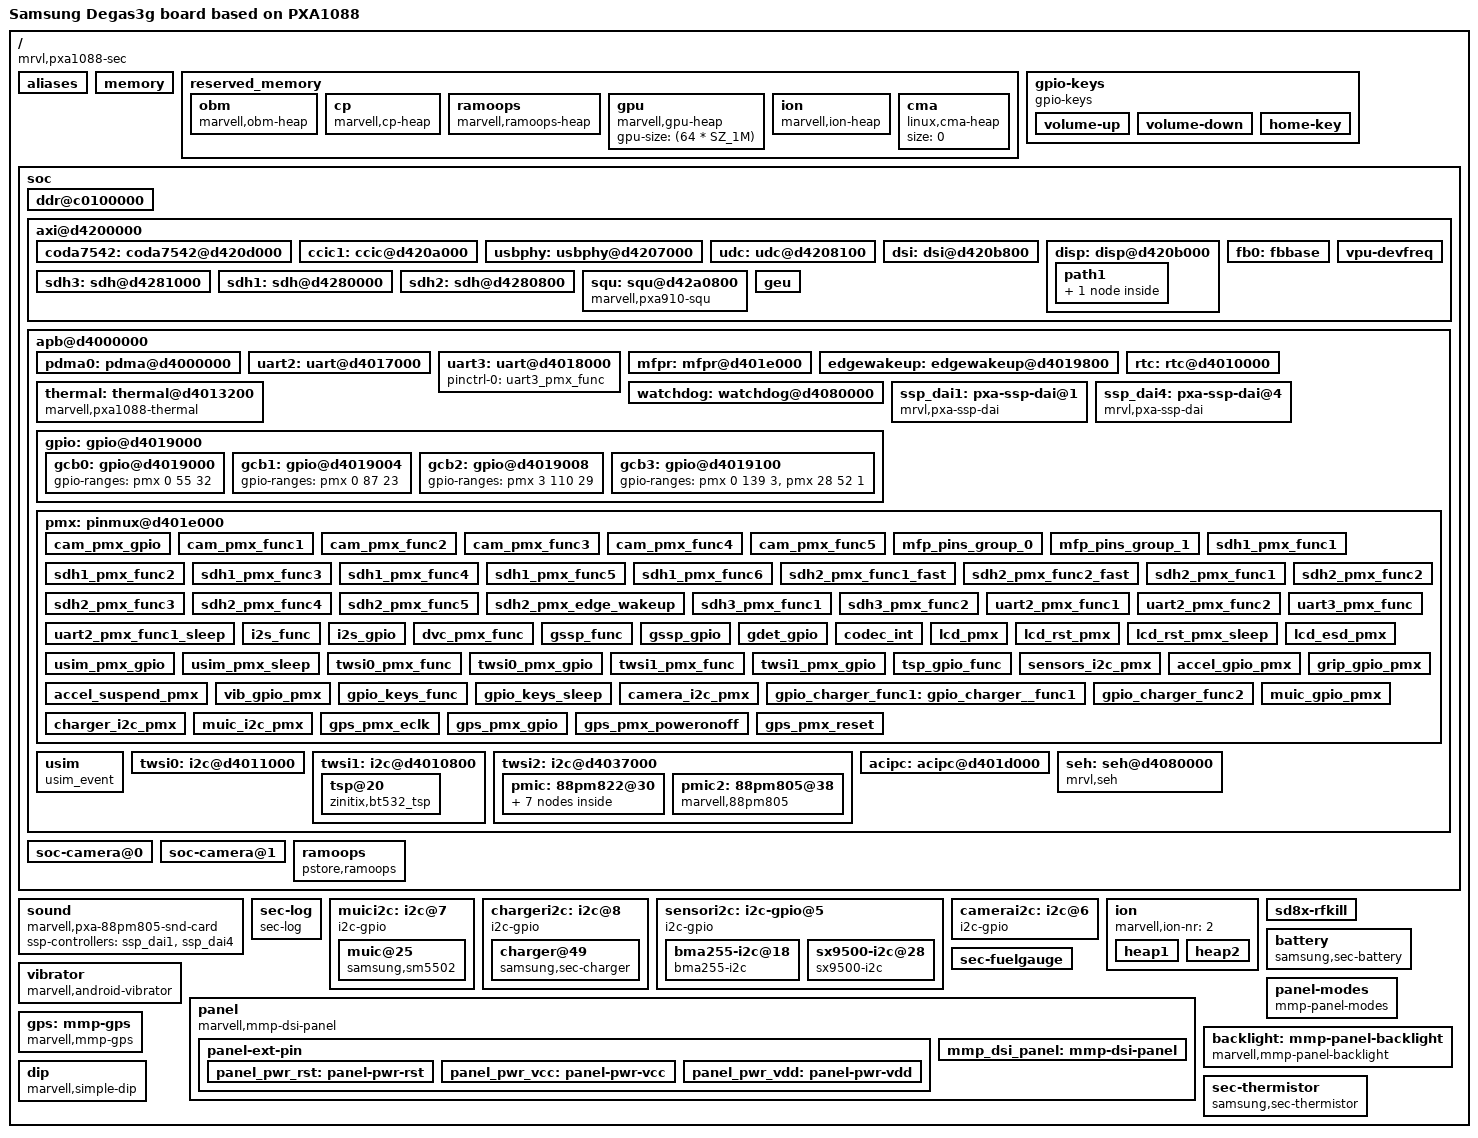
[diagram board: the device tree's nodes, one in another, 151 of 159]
/* arch/arm/boot/dts/pxa1088-degas3g-r01.dts
 * Copyright (C) 2014 Samsung Electronics Co, Ltd.
 *
 * Based on arch/arm/boot/dts/pxa1088-degas3g-r00.dts
 * Author: Shankar Bandal <shankar.b@samsung.com>
 *
 * This software is licensed under the terms of the GNU General Public
 * License version 2, as published by the Free Software Foundation,
 * and may be copied, distributed, and modified under those terms.
 *
 * This program is distributed in the hope that it will be useful,
 * but WITHOUT ANY WARRANTY; without even the implied warranty of
 * MERCHANTABILITY or FITNESS FOR A PARTICULAR PURPOSE. See the
 * GNU General Public License for more details.
 */

/dts-v1/;
#include <dt-bindings/interrupt-controller/irq.h>
#include <dt-bindings/gpio/gpio.h>
#include <dt-bindings/mmc/pxa_sdhci.h>
#include <dt-bindings/linux/sizes.h>
#include <dt-bindings/video/mmp_disp.h>

#include "sec-machtypes.h"
#include "sec-pxa1x88-pinfunc.h"
#include "pxa1088.dtsi"

/ {
	model = "Samsung Degas3g board based on PXA1088";
	compatible = "mrvl,pxa1088-sec", "mrvl,pxa1088";
	pxa,rev-id = <MACH_TYPE_DEGAS3G 1>;

	aliases {
		i2c7 = &muici2c;
		i2c8 = &chargeri2c;
		i2c5 = &sensori2c;
		i2c6 = &camerai2c;
	};

	memory {
		/* Memory Banks
		 * Bank 1 : Base 0x00000000
		 *	    Size 512 MB
		 * Bank 2 : Base 0x20000000
		 *	    Size 512 MB
		 */
		reg = <0x00000000 0x20000000 0x20000000 0x20000000>;
	};

	reserved_memory {

		obm {
			compatible = "marvell,obm-heap";
			obm-base-default = <0x00000000>;
			obm-base-with-tz = <0x01000000>;
			obm-base-with-crash-dump = <0x06000000>;
			obm-size = <(SZ_1M)>;
			status = "okay";
		};

		cp {
			compatible = "marvell,cp-heap";
			cp-base = <0x06000000>;
			cp-size = <(32 * SZ_1M)>;
			status = "okay";
		};

		/* ramoops buffer (256KB) */
		ramoops {
			compatible = "marvell,ramoops-heap";
			ramoops-base = <0x08100000>;
			ramoops-size = <(256 * SZ_1K)>;
			status = "okay";
		};

		gpu {
			compatible = "marvell,gpu-heap";
			gpu-size = <(64 * SZ_1M)>;
			status = "okay";
		};

		ion {
			compatible = "marvell,ion-heap";
			ion-base = <0x09000000>;
			ion-size = <(112 * SZ_1M)>;
			status = "okay";
		};

		cma {
			compatible = "linux,cma-heap";
			size = <0>;
			status = "okay";
		};
	};

	gpio-keys {
		compatible = "gpio-keys";
		pinctrl-names = "default", "sleep";
		pinctrl-0 = <&gpio_keys_func>;
		pinctrl-1 = <&gpio_keys_sleep>;
		edge-wakeup-gpio = <13>;
		status = "okay";
		volume-up {
			label = "Volume_up";
			gpios = <&gpio 1 GPIO_ACTIVE_LOW>;
			linux,code = <115>; /* KEY_VOLUMEUP */
			debounce-interval = <30>;
		};
		volume-down {
			label = "Volume_down";
			gpios = <&gpio 2 GPIO_ACTIVE_LOW>;
			linux,code = <114>;/* KEY_VOLUMEDOWN */
			debounce-interval = <30>;
		};
		home-key {
			label = "Home_key";
			gpios = <&gpio 13 GPIO_ACTIVE_LOW>;
			linux,code = <102>;/* HOME_KEY */
			debounce-interval = <30>;
			gpio-key,wakeup;
		};
	};

	soc {
		ddr@c0100000 {  /* DDR memory controller */
			status = "okay";
		};

		axi@d4200000 {	/* AXI */
			coda7542: coda7542@d420d000 {
				marvell,sram-internal = <1>;
				marvell,nv21_support = <0>;
				status = "okay";
			};
			ccic1: ccic@d420a000 {
				cam_avdd-supply = <&ldo4>;
				cam_io-supply = <&ldo9>;
				cam_core-supply = <&buck5>;
				cam_stby = <&gpio 14 0>;
				cam_rst = <&gpio 15 0>;
				vt_cam_stby = <&gpio 82 0>;
				vt_cam_rst = <&gpio 81 0>;
				pinctrl-names = "default","enable";
				pinctrl-0 = <&cam_pmx_gpio &cam_pmx_func2 &cam_pmx_func3 &cam_pmx_func4 &cam_pmx_func5>;
				pinctrl-1 = <&cam_pmx_func1 &cam_pmx_func2 &cam_pmx_func3 &cam_pmx_func4 &cam_pmx_func5>;
   			       mclk-gpio = <&gpio 77 0>;
				status = "okay";
			};

			usbphy: usbphy@d4207000 {
				status = "okay";
			};

			udc: udc@d4208100 {
				status = "okay";
			};

			dsi: dsi@d420b800 {
				marvell,phy-name = "mmp_dsi1";
				marvell,plat-path-name = "mmp_pnpath";
				marvell,dsi-lanes = <4>;
				marvell,burst-mode = <2>;
				marvell,hbp-en;
				marvell,hfp-en;
				status = "okay";
			};

			disp: disp@d420b000 {
				marvell,disp-name = "disp_name";
				marvell,path-num = <1>;
				lpm-qos-d1p = <PM_QOS_CPUIDLE_BLOCK_AXI>;
				status = "okay";
				path1 {
					marvell,path-name = "mmp_pnpath";
					marvell,overlay-num = <1>;
					marvell,overlay-table = <PN_GRA>;
					marvell,output-type = <PATH_OUT_DSI>;
					marvell,path-config = <0x10>;
					marvell,link-config = <0x1>;
					WVGA {
						disp1_clksrc = "pll1_416m";
						dsipll_clksrc = "pll3";
						pn_sclk_clksrc = "disp1";
					};
				};
			};

			fb0: fbbase {
				marvell,fb-name = "mmp-fb";
				marvell,path-name = "mmp_pnpath";
				marvell,overlay-id = <PN_GRA>;
				marvell,default-pixfmt = <PIXFMT_RGBA888>;
				marvell,buffer-num = <3>;
				marvell,fb-mem = <0x17000000>;
				status = "okay";
			};

			/* eMMC */
			sdh3: sdh@d4281000 {
				pinctrl-names = "default";
				pinctrl-0 = <&sdh3_pmx_func1 &sdh3_pmx_func2>;
				bus-width = <8>;
				non-removable;
				marvell,sdh-pm-runtime-en;
				marvell,sdh-quirks = <(SDHCI_QUIRK_BROKEN_CARD_DETECTION)>;
				marvell,sdh-quirks2 = <(SDHCI_QUIRK2_BUS_CLK_GATE_ENABLED)>;
				marvell,sdh-host-caps = <(MMC_CAP_1_8V_DDR)>;
				marvell,sdh-host-caps2 = <(
							MMC_CAP2_DISABLE_BLK_ASYNC |
							MMC_CAP2_CACHE_CTRL
						)>;
				marvell,sdh-flags = <(
						PXA_FLAG_SD_8_BIT_CAPABLE_SLOT |
						PXA_FLAG_ENABLE_CLOCK_GATING |
						PXA_FLAG_TX_SEL_BUS_CLK
					      )>;
				/* prop "sdh-dtr-data": <timing preset_rate src_rate tx_delay rx_delay> */
				marvell,sdh-dtr-data = <PXA_MMC_TIMING_LEGACY PXA_SDH_DTR_26M PXA_SDH_DTR_104M 0 0>,
						<PXA_MMC_TIMING_MMC_HS PXA_SDH_DTR_52M PXA_SDH_DTR_104M 0 0>,
						<PXA_MMC_TIMING_UHS_DDR50 PXA_SDH_DTR_52M PXA_SDH_DTR_104M 0 0>,
						<PXA_MMC_TIMING_MAX PXA_SDH_DTR_PS_NONE PXA_SDH_DTR_104M 0 0>;
				status = "okay";
			};

			/* SD card */
			sdh1: sdh@d4280000 {
				pinctrl-names = "default";
				pinctrl-0 = <&sdh1_pmx_func1 &sdh1_pmx_func2 &sdh1_pmx_func3 &sdh1_pmx_func4 &sdh1_pmx_func5 &sdh1_pmx_func6>;
				vqmmc-supply	= <&ldo5>;
				vmmc-supply	= <&ldo11>;
				cd-gpios = <&gpio 11 0>;
				cd-inverted;
				bus-width = <4>;
				wp-inverted;
				marvell,sdh-pm-runtime-en;
				marvell,sdh-host-caps-disable = <(
					MMC_CAP_UHS_SDR12
					|MMC_CAP_UHS_SDR25
					|MMC_CAP_UHS_SDR50
					|MMC_CAP_UHS_DDR50
					|MMC_CAP_UHS_SDR104
				)>;
				marvell,sdh-quirks = <(
						SDHCI_QUIRK_INVERTED_WRITE_PROTECT |
						SDHCI_QUIRK_BROKEN_CARD_DETECTION
						)>;
				marvell,sdh-quirks2 = <(SDHCI_QUIRK2_BUS_CLK_GATE_ENABLED)>;
				marvell,sdh-host-caps2 = <(MMC_CAP2_DETECT_ON_ERR)>;
				marvell,sdh-flags = <(
						PXA_FLAG_TX_SEL_BUS_CLK |
						PXA_FLAG_ENABLE_CLOCK_GATING
					      )>;
				/* prop "sdh-dtr-data": <timing preset_rate src_rate tx_delay rx_delay> */
				marvell,sdh-dtr-data = <PXA_MMC_TIMING_LEGACY PXA_SDH_DTR_26M PXA_SDH_DTR_104M 0 0>,
						<PXA_MMC_TIMING_SD_HS PXA_SDH_DTR_52M PXA_SDH_DTR_104M 0 0>,
						<PXA_MMC_TIMING_UHS_DDR50 PXA_SDH_DTR_52M PXA_SDH_DTR_104M 0 0>,
						<PXA_MMC_TIMING_MAX PXA_SDH_DTR_PS_NONE PXA_SDH_DTR_104M 0 0>;
				status = "okay";
			};

			/* SDIO */
			sdh2: sdh@d4280800 {
				pinctrl-names = "default", "fast", "sleep";
				pinctrl-0 = <&sdh2_pmx_func1 &sdh2_pmx_func2 &sdh2_pmx_func3 &sdh2_pmx_func4 &sdh2_pmx_func5>;
				pinctrl-1 = <&sdh2_pmx_func1_fast &sdh2_pmx_func2_fast &sdh2_pmx_func3 &sdh2_pmx_func4 &sdh2_pmx_func5>;
				pinctrl-2 = <&sdh2_pmx_edge_wakeup>;
				bus-width = <4>;
				mrvl,clk-delay-cycles = <0x0>;
				marvell,sdh-quirks = <(
						SDHCI_QUIRK_BROKEN_CARD_DETECTION
						)>;
				marvell,sdh-quirks2 = <(
				        SDHCI_QUIRK2_BUS_CLK_GATE_ENABLED |
				        SDHCI_QUIRK2_SDIO_SW_CLK_GATE |
				        SDHCI_QUIRK2_HOLDSUSPEND_AFTER_REQUEST
				        )>;
				marvell,sdh-host-caps2 = <(MMC_CAP2_NO_VOLTAGE_SWITCH)>;
				marvell,sdh-flags = <(
						PXA_FLAG_WAKEUP_HOST |
						PXA_FLAG_ENABLE_CLOCK_GATING |
						PXA_FLAG_TX_SEL_BUS_CLK |
						PXA_FLAG_EN_PM_RUNTIME |
						PXA_FLAG_DISABLE_PROBE_CDSCAN
					    )>;
				marvell,sdh-pm-caps = <(
			            MMC_PM_KEEP_POWER
			            )>;
				/* prop "sdh-dtr-data": <timing preset_rate src_rate tx_delay rx_delay> */
				marvell,sdh-dtr-data = <PXA_MMC_TIMING_LEGACY PXA_SDH_DTR_26M PXA_SDH_DTR_104M 0 0>,
						<PXA_MMC_TIMING_SD_HS PXA_SDH_DTR_45M PXA_SDH_DTR_89M 0 0>,
						<PXA_MMC_TIMING_UHS_SDR104 PXA_SDH_DTR_208M PXA_SDH_DTR_208M 0 0>,
						<PXA_MMC_TIMING_MAX PXA_SDH_DTR_PS_NONE PXA_SDH_DTR_89M 0 0>;
				status = "okay";
			};

			squ: squ@d42a0800 {
				compatible = "marvell,pxa910-squ";
				reg = <0xd42a0800 0x100>;
				interrupts = <0 46 0x4>;
				#dma-cells = <1>;
				asram = <&sram>;
			};

			vpu-devfreq {
				status = "okay";
			};
			geu: geu {
				status = "okay";
			};
		};

		apb@d4000000 {
			pdma0: pdma@d4000000 {
				status = "okay";
			};

			uart2: uart@d4017000 {
				pinctrl-names = "default", "sleep";
				pinctrl-0 = <&uart2_pmx_func1 &uart2_pmx_func2>;
				pinctrl-1 = <&uart2_pmx_func1_sleep &uart2_pmx_func2>;
				edge-wakeup-gpio = <47>; /* GPIO47: UART rx pin */
				status = "okay";
			};

			uart3: uart@d4018000 {
				pinctrl-names = "default";
				pinctrl-0 = <&uart3_pmx_func>;
				status = "okay";
			};

			mfpr: mfpr@d401e000 {
				pinctrl-names = "default";
				reg = <0xd401e000 0x280>;
				pinctrl-0 = <&mfp_pins_group_0 &mfp_pins_group_1>;
				status = "ok";
			};

			edgewakeup: edgewakeup@d4019800 {
				status = "ok";
			};

			rtc: rtc@d4010000 {
				status = "okay";
			};

			thermal: thermal@d4013200 {
				compatible = "marvell,pxa1088-thermal";
				reg = <0xd4013200 0x50>;
				interrupts = <0 60 0x4>;
				trigger_levels_count = <0>;
				type = <0>;
				status = "ok";
			};

			watchdog: watchdog@d4080000 {
				status = "okay";
			};

			ssp_dai1: pxa-ssp-dai@1 {
				compatible = "mrvl,pxa-ssp-dai";
				reg = <0x1 0x0>;
				port = <&ssp1>;
				pinctrl-names = "default","ssp";
				pinctrl-0 = <&i2s_gpio>;
				pinctrl-1 = <&i2s_func>;
				ssp-gpio = <&gpio 21 0 &gpio 22 0 &gpio 23 0 &gpio 24 0>;
				dmas = <&squ 1
					&squ 0>;
				dma-names = "rx", "tx";
				asram = <&sram>;
				platform_driver_name = "tdma_platform";
				burst_size = <4>;
				playback_period_bytes = <4096>;
				playback_buffer_bytes = <20480>;
				capture_period_bytes = <4096>;
				capture_buffer_bytes = <20480>;
			};

			ssp_dai4: pxa-ssp-dai@4 {
				compatible = "mrvl,pxa-ssp-dai";
				reg = <0x4 0x0>;
				port = <&ssp4>;
				pinctrl-names = "default","ssp";
				pinctrl-0 = <&gssp_gpio>;
				pinctrl-1 = <&gssp_func>;
				ssp-gpio = <&gpio 25 0 &gpio 26 0 &gpio 27 0 &gpio 28 0>;
				dmas = <&pdma0 6 0
					&pdma0 7 0>;
				dma-names = "rx", "tx";
				platform_driver_name = "pdma_platform";
				burst_size = <8>;
				playback_period_bytes = <4096>;
				playback_buffer_bytes = <131072>;
				capture_period_bytes = <4096>;
				capture_buffer_bytes = <131072>;
			};

			gpio: gpio@d4019000 {
				status = "okay";
				/*
				 * In theorical, some gpios could be routed to
				 * multiple pins. So define the gpio-ranges in
				 * board file, not silicon file.
				 */
				gcb0: gpio@d4019000 {
					/* gpio offset, pin offset, nr pins */
					gpio-ranges = <&pmx 0 55 32>;
				};
				gcb1: gpio@d4019004 {
					gpio-ranges = <&pmx 0 87 23>;
				};
				gcb2: gpio@d4019008 {
					gpio-ranges = <&pmx 3 110 29>;
				};
				gcb3: gpio@d4019100 {
					gpio-ranges = <&pmx 0 139 3  &pmx 28 52 1>;
				};
			};

			pmx: pinmux@d401e000 {
				/* pin base, nr pins & gpio function */
				pinctrl-single,gpio-range = <
					/*
					 * GPIO number is hardcoded for range at here.
					 * In gpio chip, GPIO number is not hardcoded for range.
					 * Since one gpio pin may be routed to multiple pins,
					 * define these gpio range in pxa910-dkb.dts not pxa910.dtsi.
					 */
					&range 55 55 0	/* GPIO0 ~ GPIO54 */
					&range 110 32 0 /* GPIO67 ~ GPIO98 */
					&range 17 1 1   /* GPIO101 */
					&range 52 1 0	/* GPIO124 */
				>;

				cam_pmx_gpio: cam_pmx_gpio {
					pinctrl-single,pins = <
						GPIO77 AF0
					>;
					DS_MEDIUM;PULL_DOWN;EDGE_NONE;LPM_DRIVE_LOW;
				};
				cam_pmx_func1: cam_pmx_func1 {
					pinctrl-single,pins = <
						GPIO77 AF1
					>;
					DS_SLOW1;PULL_DOWN;EDGE_NONE;LPM_DRIVE_LOW;
				};
				cam_pmx_func2: cam_pmx_func2 {
					pinctrl-single,pins = <
						GPIO67 AF1
						GPIO68 AF1
						GPIO69 AF1
						GPIO70 AF1
						GPIO71 AF1
						GPIO72 AF1
						GPIO73 AF1
						GPIO74 AF1
						GPIO75 AF1
						GPIO76 AF1
					>;
					MFP_LPM_DRIVE_LOW;
				};

				cam_pmx_func3: cam_pmx_func3 {
					pinctrl-single,pins = <
						GPIO78 AF1
					>;
					PULL_DOWN;
				};

				cam_pmx_func4: cam_pmx_func4 {
					pinctrl-single,pins = <
						GPIO14 AF0
						GPIO15 AF0
					>;
					DS_MEDIUM;PULL_DOWN;EDGE_NONE;LPM_DRIVE_LOW;
				};

				cam_pmx_func5: cam_pmx_func5 {
					pinctrl-single,pins = <
						GPIO81 AF0
						GPIO82 AF0
					>;
					DS_MEDIUM;PULL_DOWN;EDGE_NONE;LPM_DRIVE_LOW;
				};

				/* MFP_LPM_FLOAT */
				mfp_pins_group_0: mfp_pins_group_0 {
					pinctrl-single,pins = <
						DF_IO8 AF1
						DF_IO9 AF1
						DF_IO10 AF1
						DF_IO11 AF1
						DF_IO12 AF1
						DF_IO13 AF1
						DF_WEn AF0
						DF_REn AF0
						DF_ALE_SM_WEn AF0
						DF_RDY0 AF1
						DF_RDY1 AF0
						DF_nCS1_SM_nCS3 AF1
						SM_nCS0 AF1
						SM_nCS1 AF1
						GPIO98 AF0
						GPIO123 AF1
						SM_BE0 AF0
						VCXO_REQ AF1
					>;
					PULL_UP;LPM_FLOAT;
				};

				mfp_pins_group_1: mfp_pins_group_1 {
					pinctrl-single,pins = <
						GPIO9 AF0
						DF_IO14 AF1
						DF_IO15 AF1
					>;
					PULL_NONE;LPM_FLOAT;
				};

				/* MFP_PULL_LOW | MFP_LPM_FLOAT */
				sdh1_pmx_func1: sdh1_pmx_func1 {
					pinctrl-single,pins = <
						MMC1_DAT7 AF0
						MMC1_DAT6 AF0
						MMC1_DAT5 AF0
						MMC1_DAT4 AF0
						MMC1_WP AF0
					>;
					DS_MEDIUM;PULL_DOWN;EDGE_NONE;LPM_FLOAT;
				};

				/* no pull, no LPM */
				sdh1_pmx_func2: sdh1_pmx_func2 {
					pinctrl-single,pins = <
						MMC1_DAT3 AF0
						MMC1_DAT2 AF0
						MMC1_DAT1 AF0
						MMC1_DAT0 AF0
					>;
					MFP_DEFAULT;
				};

				/* MFP_LPM_DRIVE_LOW */
				sdh1_pmx_func3: sdh1_pmx_func3 {
					pinctrl-single,pins = <
						MMC1_CLK AF0
					>;
					MFP_LPM_DRIVE_LOW;
				};

				/* MFP_PULL_HIGH */
				sdh1_pmx_func4: sdh1_pmx_func4 {
					pinctrl-single,pins = <
						MMC1_CD AF0
					>;
					DS_MEDIUM;PULL_HIGH;EDGE_NONE;LPM_NONE;
				};

				/* MFP_PULL_UP */
				sdh1_pmx_func5: sdh1_pmx_func5 {
					pinctrl-single,pins = <
						MMC1_CMD AF0
					>;
					PULL_UP;LPM_FLOAT;
				};

				/* SD_DETECT */
				sdh1_pmx_func6: sdh1_pmx_func6 {
					pinctrl-single,pins = <
						GPIO11 AF0
					>;
					MFP_LPM_FLOAT;
				};

				sdh2_pmx_func1_fast: sdh2_pmx_func1_fast {
						pinctrl-single,pins = <
							GPIO37 AF1
							GPIO38 AF1
							GPIO39 AF1
							GPIO40 AF1
							GPIO41 AF1
						>;
						DS_SLOW0;PULL_NONE;EDGE_NONE;LPM_NONE;
				};

				sdh2_pmx_func2_fast: sdh2_pmx_func2_fast {
						pinctrl-single,pins = <
							GPIO42 AF1
						>;
						DS_SLOW0;PULL_NONE;EDGE_NONE;LPM_DRIVE_LOW;
				};

				sdh2_pmx_func1: sdh2_pmx_func1 {
					pinctrl-single,pins = <
						GPIO37 AF1
						GPIO38 AF1
						GPIO39 AF1
						GPIO40 AF1
						GPIO41 AF1
					>;
					DS_SLOW0;PULL_NONE;EDGE_NONE;LPM_NONE;
				};
				/* WLAN_WU_HOST */
				sdh2_pmx_func2: sdh2_pmx_func2 {
					pinctrl-single,pins = <
						GPIO84 AF0
					>;
					DS_MEDIUM;PULL_DOWN;EDGE_NONE;LPM_NONE;
				};
				/* WLAN_PDn */
				sdh2_pmx_func3: sdh2_pmx_func3 {
					pinctrl-single,pins = <
						GPIO51 AF0
					>;
					DS_MEDIUM;PULL_FLOAT;EDGE_NONE;
				};
				/* HOST_WU_WLAN */
				sdh2_pmx_func4: sdh2_pmx_func4 {
					pinctrl-single,pins = <
						GPIO83 AF0
					>;
					DS_MEDIUM;PULL_FLOAT;EDGE_NONE;LPM_DRIVE_LOW;
				};
				/* WLAN_SD_CLK */
				sdh2_pmx_func5: sdh2_pmx_func5 {
					pinctrl-single,pins = <
						GPIO42 AF1
					>;
					DS_SLOW0;PULL_NONE;EDGE_NONE;LPM_DRIVE_LOW;
				};

				sdh2_pmx_edge_wakeup: sdh2_pmx_edge_wakeup {
						pinctrl-single,pins = <
							GPIO39 AF1
						>;
						DS_MEDIUM;PULL_LOW;EDGE_BOTH;LPM_NONE;
				};

				/* no pull, no LPM */
				sdh3_pmx_func1: sdh3_pmx_func1 {
					pinctrl-single,pins = <
						ND_IO7 AF1
						ND_IO6 AF1
						ND_IO5 AF1
						ND_IO4 AF1
						ND_IO3 AF1
						ND_IO2 AF1
						ND_IO1 AF1
						ND_IO0 AF1
						ND_CLE_SM_OEN AF1
						SM_BEN0 AF2
					>;
					DS_MEDIUM;PULL_UP;EDGE_NONE;LPM_FLOAT;
				};

				/* MFP_LPM_DRIVE_LOW */
				sdh3_pmx_func2: sdh3_pmx_func2 {
					pinctrl-single,pins = <
						SM_SCLK AF1
					>;
					MFP_LPM_DRIVE_LOW;
				};

				uart2_pmx_func1: uart2_pmx_func1 {
					pinctrl-single,pins = <
						GPIO47 AF6
					>;
					MFP_PULL_UP;
				};

				uart2_pmx_func2: uart2_pmx_func2 {
					pinctrl-single,pins = <
						GPIO48 AF6
					>;
					MFP_PULL_UP;
				};

				uart2_pmx_func1_sleep: uart2_pmx_func1_sleep {
					pinctrl-single,pins = <
						GPIO47 AF6
					>;
					MFP_PULL_UP;
				};

				uart3_pmx_func: uart3_pmx_func {
					pinctrl-single,pins = <
						GPIO45 AF1
						GPIO46 AF1
					>;
					MFP_DEFAULT;
				};

				i2s_func: i2s_func {
					pinctrl-single,pins = <
						GPIO21 AF1
						GPIO22 AF1
						GPIO23 AF1
						GPIO24 AF1
					>;
					MFP_PULL_UP;
				};

				i2s_gpio: i2s_gpio {
					pinctrl-single,pins = <
						GPIO21 AF0
						GPIO22 AF0
						GPIO23 AF0
						GPIO24 AF0
					>;
					MFP_PULL_UP;
				};

				/* no pull, no LPM */
				dvc_pmx_func: dvc_pmx_func {
					pinctrl-single,pins = <
						GPIO43 AF6
						GPIO44 AF6
					>;
					MFP_DEFAULT;
				};

				gssp_func: gssp_func {
					pinctrl-single,pins = <
						GPIO25 AF1
						GPIO26 AF1
						GPIO27 AF1
						GPIO28 AF1
					>;
					MFP_DEFAULT;
				};

				gssp_gpio: gssp_gpio {
					pinctrl-single,pins = <
						GPIO25 AF0
						GPIO26 AF0
						GPIO27 AF0
						GPIO28 AF0
					>;
					MFP_PULL_UP;
				};

				gdet_gpio: gdet_gpio {
					pinctrl-single,pins = <
						GPIO97 AF0
					>;
					MFP_PULL_UP;LPM_PULLHIGH;
				};
				
				codec_int: codec_int {
					pinctrl-single,pins = <
						GPIO124 AF0
					>;
					MFP_PULL_UP;LPM_PULLHIGH;
				};

				/* MFP_LPM_FLOAT */
				lcd_pmx: lcd_pmx {
					pinctrl-single,pins = <
						GPIO6 AF0
						GPIO7 AF0
					>;
					DS_MEDIUM;PULL_FLOAT;EDGE_NONE;LPM_DRIVE_LOW;
				};

				/* MFP_PULL_UP */
				lcd_rst_pmx: lcd_rst_pmx {
					pinctrl-single,pins = <
						GPIO18 AF0
					>;
					MFP_PULL_UP;
				};

				/* MFP_PULL_LOW | MFP_LPM_DRIVE_LOW */
				lcd_rst_pmx_sleep: lcd_rst_pmx_sleep {
					pinctrl-single,pins = <
						GPIO18 AF0
					>;
					DS_MEDIUM;PULL_DOWN;EDGE_NONE;LPM_DRIVE_LOW;
				};

				lcd_esd_pmx: lcd_esd_pmx {
					pinctrl-single,pins = <
						GPIO19 AF0
					>;
					DS_MEDIUM;PULL_NONE;EDGE_NONE;LPM_DRIVE_HIGH;
				};

				/* MFP_LPM_FLOAT SIM Detect Pin */
				usim_pmx_gpio: usim_pmx_gpio {
					pinctrl-single,pins = <
						GPIO101 AF1
					>;
					DS_MEDIUM;PULL_UP;EDGE_NONE;LPM_FLOAT;
				};
				
				usim_pmx_sleep: usim_pmx_sleep {
					pinctrl-single,pins = <
						GPIO101 AF1
					>;
					DS_MEDIUM;PULL_UP;EDGE_BOTH;LPM_NONE;
				};

				twsi0_pmx_func: twsi0_pmx_func {
					pinctrl-single,pins = <
						GPIO79 AF1
						GPIO80 AF1
					>;
					MFP_LPM_FLOAT;
				};
				twsi0_pmx_gpio: twsi0_pmx_gpio {
					pinctrl-single,pins = <
						GPIO79 AF0
						GPIO80 AF0
					>;
					MFP_LPM_FLOAT;
				};
				twsi1_pmx_func: twsi1_pmx_func {
					pinctrl-single,pins = <
						GPIO87 AF5
						GPIO88 AF5
					>;
					MFP_LPM_FLOAT;
				};

				twsi1_pmx_gpio: twsi1_pmx_gpio {
					pinctrl-single,pins = <
						GPIO87 AF0
						GPIO88 AF0
					>;
					MFP_LPM_FLOAT;
				};
				tsp_gpio_func: tsp_gpio_func {
					pinctrl-single,pins = <
						GPIO94 AF0
					>;
					MFP_DEFAULT;
				};

				sensors_i2c_pmx: sensors_i2c_pmx {
					pinctrl-single,pins = <
						GPIO35 AF0
						GPIO36 AF0
					>;
					DS_MEDIUM;EDGE_NONE;PULL_NONE;LPM_FLOAT;
				};

				accel_gpio_pmx: accel_gpio_pmx {
					pinctrl-single,pins = <
						GPIO10 AF0
					>;
					DS_MEDIUM;PULL_DOWN;EDGE_NONE;
				};

				accel_suspend_pmx: accel_suspend_pmx {
					pinctrl-single,pins = <
						GPIO10 AF0
					>;
					DS_MEDIUM;PULL_DOWN;EDGE_NONE;
				};

				grip_gpio_pmx: grip_gpio_pmx {
					pinctrl-single,pins = <
						GPIO34 AF0
					>;
					DS_MEDIUM;PULL_UP;EDGE_NONE;
				};

				vib_gpio_pmx: vib_gpio_pmx {
					pinctrl-single,pins = <
						GPIO96 AF0
					>;
					MFP_PULL_DOWN;
				};

				gpio_keys_func: gpio_keys_func{
					pinctrl-single,pins = <
						GPIO1 AF0
						GPIO2 AF0
						GPIO13 AF0
					>;
					DS_MEDIUM;PULL_NONE;EDGE_NONE;LPM_FLOAT;
				};

				gpio_keys_sleep: gpio_keys_sleep {
					pinctrl-single,pins = <
						GPIO13 AF0
					>;
					DS_MEDIUM;PULL_UP;EDGE_BOTH;LPM_NONE;
				};

				camera_i2c_pmx: camera_i2c_pmx {
					pinctrl-single,pins = <
						GPIO30 AF0
						GPIO29 AF0
					>;
					MFP_LPM_FLOAT;
				};
				gpio_charger_func1: gpio_charger__func1 {
					pinctrl-single,pins = <
						GPIO8 AF0
						>;
					MFP_DEFAULT;
				};

				gpio_charger_func2: gpio_charger_func2 {
					pinctrl-single,pins = <
						GPIO20 AF0
					>;
					DS_MEDIUM;PULL_DOWN;EDGE_NONE;LPM_NONE;
				};
				muic_gpio_pmx: muic_gpio_pmx {
					pinctrl-single,pins = <
						GPIO93 AF0
					>;
					MFP_LPM_FLOAT;
				};

				charger_i2c_pmx: charger_i2c_pmx {
					pinctrl-single,pins = <
						GPIO17 AF0
						GPIO16 AF0
					>;
					DS_MEDIUM;PULL_UP;EDGE_NONE;LPM_FLOAT;
				};

				muic_i2c_pmx: muic_i2c_pmx {
					pinctrl-single,pins = <
						GPIO50 AF0
						GPIO49 AF0
					>;
					MFP_LPM_FLOAT;
				};
				gps_pmx_eclk: gps_pmx_eclk {
					/* eclk */
					pinctrl-single,pins = <
						GPIO89 AF5
					>;
					MFP_DEFAULT;
				};
				gps_pmx_gpio: gps_pmx_gpio {
					/* gpio */
					pinctrl-single,pins = <
						GPIO89 AF0
					>;
					MFP_DEFAULT;
				};
				gps_pmx_poweronoff: gps_pmx_poweronoff {
					pinctrl-single,pins = <
						GPIO4 AF0
					>;
					MFP_PULL_DOWN;MFP_LPM_DIRVE_LOW;
				};
				gps_pmx_reset: gps_pmx_reset {
					pinctrl-single,pins = <
						GPIO5 AF0
					>;
					MFP_PULL_UP;MFP_LPM_DIRVE_HIGH;
				};
			};

			usim: usim {
				compatible = "usim_event";
				pinctrl-names = "default", "sleep";
				pinctrl-0 = <&usim_pmx_gpio>;
				pinctrl-1 = <&usim_pmx_sleep>;
				edge-wakeup-gpio = <101>;
				status = "okay";
			};

			twsi0: i2c@d4011000 {
				pinctrl-names = "default","gpio";
				pinctrl-0 = <&twsi0_pmx_func>;
				pinctrl-1 = <&twsi0_pmx_gpio>;
				i2c-gpio = <&gpio 79 0 &gpio 80 0>;
				marvell,i2c-always-on;
				status = "okay";
			};

			twsi1: i2c@d4010800 {
				pinctrl-names = "default", "gpio";
				pinctrl-0 = <&twsi1_pmx_func>;
				pinctrl-1 = <&twsi1_pmx_gpio>;
				i2c-gpio = <&gpio 87 0 &gpio 88 0>;
				marvell,i2c-always-on;
				status = "okay";
				tsp@20 {
					compatible = "zinitix,bt532_tsp";
					pinctrl-names = "default";
					pinctrl-0 = <&tsp_gpio_func>;
					reg = <0x20>;
					interrupt-parent = <&gpio>;
					interrupts = <94 IRQ_TYPE_EDGE_FALLING>;
					bt532,x_resolution = /bits/ 16 <799>;
					bt532,y_resolution = /bits/ 16 <1279>;
					bt532,orientation = /bits/ 8 <0>;
					bt532,page_size = /bits/ 16 <128>;
					tsp_gpio = <&gpio 94 GPIO_ACTIVE_LOW>;
					tsp_vdd_supply_type = <1>;
					tsp_vdd-supply = <&ldo1>;
				};
			};

			twsi2: i2c@d4037000 {
				status = "okay";

				pmic: 88pm822@30 {
					reg = <0x30>;
					interrupts = <0 4 0x4>;
					interrupt-parent = <&gic>;
					dvc {
						compatible = "marvell,88pm8xx-dvc";
						/* pm822 dvc affect buck1/3/5, affected 32bit = (1 << 4) | (1 << 2) | (1 << 0)*/
						dvc-affected-buckbits = <21>;
						pinctrl-names = "default";
						pinctrl-0 = <&dvc_pmx_func>;
					};
					usb: usb {
						compatible = "marvell,88pm80x-usb";
						vbus-gpio = <0xff>;
						id-gpadc = <0xff>;
					};

				};
				pmic2: 88pm805@38 {
					compatible = "marvell,88pm805";
					reg = <0x38>;
					interrupt-parent = <&gpio>;
					interrupts = <124 0x1>;
					marvell,88pm805-irq-write-clear;
					pinctrl-names = "default";
					pinctrl-0 = <&codec_int>;						
				};
			};

			acipc: acipc@d401d000 {
				status = "okay";
			};

			seh: seh@d4080000 {
				compatible = "mrvl,seh";
				reg = <0xd4080000 0x100>;
				interrupts = <0 35 0x4>;
				interrupt-names = "WDT";
				watchdog-type = <0>; /* wdt timer */
				status = "okay";
			};

		};
		soc-camera@0 {
			 status = "okay";
		};
		soc-camera@1 {
			status = "okay";
		};

		/*
		 * ramoops:
		 * 256 KB memory starts at 0x8100000
		 * pstore dump: 2 chunks, totall 64 KB, 32 KB each
		 * console size: 192 KB
		 * no dump_oops
		 */
		ramoops {
			compatible = "pstore,ramoops";
			mem-size = <0x40000>;
			mem-address = <0x8100000>;
			record-size = <0x8000>;
			console-size = <0x30000>;
			dump-oops = <0>;
			status = "okay";
		};

	};
	sound {
		compatible = "marvell,pxa-88pm805-snd-card";
		ssp-controllers = <&ssp_dai1 &ssp_dai4>;
	};
		sec-log {
                        compatible = "sec-log";
                        status = "okay";
                };
	muici2c: i2c@7 {
		compatible = "i2c-gpio";
		reg = <0x2 0x0>;

		gpios = <&gpio 50 0
			&gpio 49 0>;
		/*
		i2c-gpio,sda-open-drain;
		i2c-gpio,scl-open-drain;
		*/
		i2c-gpio,delay-us = <3>;
		i2c-gpio,timeout-ms = <100>;

		#address-cells = <1>;
		#size-cells = <0>;
		pinctrl-names = "default";
		pinctrl-0 = <&muic_i2c_pmx>;

		status = "okay";

		muic@25 {
			compatible = "samsung,sm5502";
			pinctrl-names = "default","sleep";
			pinctrl-0 = <&muic_gpio_pmx>;
			reg = <0x25>;
			interrupt-parent = <&gpio>;
			interrupts = <93 IRQ_TYPE_EDGE_RISING>;
			connector-gpio = <&gpio 93 0>;
			lpm-qos = <PM_QOS_CPUIDLE_BLOCK_AXI>;
		};
	};


	chargeri2c: i2c@8 {
            compatible = "i2c-gpio";
		reg = <0x3 0x0>;
		gpios = <&gpio 17 0
		&gpio 16 0>;
		/*
		i2c-gpio,sda-open-drain;
		i2c-gpio,scl-open-drain;
		*/
		i2c-gpio,delay-us = <3>;
		i2c-gpio,timeout-ms = <100>;

		#address-cells = <1>;
		#size-cells = <0>;
		pinctrl-names = "default";
		pinctrl-0 = <&charger_i2c_pmx>;

		status = "okay";
		charger@49 {
			compatible = "samsung,sec-charger";
			pinctrl-names = "default";
			pinctrl-0 = <&gpio_charger_func1 &gpio_charger_func2>;
			reg = <0x49>;
			interrupt-parent = <&gpio>;
			chgirq-gpio = <&gpio 8 0>;
			chgen-gpio = <&gpio 20 0>;
			chg-irq-attr = <IRQ_TYPE_EDGE_BOTH>;
			chg-float-voltage = <4350>;
		};
	};

	sensori2c: i2c-gpio@5 {
		compatible = "i2c-gpio";
		gpios = <&gpio 36 0
			 &gpio 35 0>;

		pinctrl-names = "default";
		pinctrl-0 = <&sensors_i2c_pmx>;

		status = "okay";

		#address-cells = <1>;
		#size-cells = <0>;

		bma255-i2c@18 {
			compatible = "bma255-i2c";
			pinctrl-names = "default","sleep";
			pinctrl-0 = <&accel_gpio_pmx>;
			pinctrl-1 = <&accel_suspend_pmx>;
			reg = <0x18>;
			interrupt-parent = <&gpio>;
			interrupts = <10 IRQ_TYPE_EDGE_RISING>;
			acc_int = <&gpio 10 0>;
			acc_chip_pos = <7>;
		};
		sx9500-i2c@28 {
			compatible = "sx9500-i2c";
			pinctrl-names = "default","sleep";
			pinctrl-0 = <&grip_gpio_pmx>;
			reg = <0x28>;
			interrupt-parent = <&gpio>;
			interrupts = <34 IRQ_TYPE_EDGE_FALLING>;
			grip_Nirq = <&gpio 33 0>;
		};
	};

	camerai2c: i2c@6 {
		compatible = "i2c-gpio";
		gpios = <&gpio 30 0	/* SDA */
		&gpio 29 0>;/* SCL */
		i2c-gpio,delay-us = <3>;
		i2c-gpio,timeout-ms = <100>;
		pinctrl-names = "default";
		pinctrl-0 = <&camera_i2c_pmx>;
		status = "okay";
	};

	ion {
		marvell,ion-nr = <2>;
		status = "okay";

		heap1 {
			marvell,ion-name = "carveout_heap";
			marvell,ion-type = <2>;
			marvell,ion-id = <2>;
		};

		heap2 {
			marvell,ion-name = "system_heap";
			marvell,ion-type = <0>;
			marvell,ion-id = <0>;
		};
	};

	sd8x-rfkill {
		sd-host = <&sdh2>;
		pd-gpio = <&gpio 51 0>;
		/* rst-gpio = <&gpio 0 0>; */
		edge-wakeup-gpio = <&gpio 39 0>;
		hostwu-gpio = <&gpio 83 0>;
		v_wib_3v3-supply=<&ldo10>;
		status = "okay";
	};

	battery {
		status = "okay";
		compatible = "samsung,sec-battery";

		vendor = "SDI SDI";
		charger_name = "sec-charger";
		fuelgauge_name = "sec-fuelgauge";
		technology = <2>; /* POWER_SUPPLY_TECHNOLOGY_LION */

		chip_vendor = "LSI";
		polling_time = <10 30 30 30 3600>;

		temp_table_adc = <276 326 383 455 530 629 740 787 866 1013
			1181 1361 1564 1792 2024 2263 2493 2728 2948 3011
			3135 3208 3313 3465 3588 3698 3779>;
		temp_table_data = <900 850 800 750 700 650 600 580 550 500
			450 400 350 300 250 200 150 100 50 30
			0 (-20) (-50) (-100) (-150) (-200) (-250)>;

		input_current_limit = <950 0 0 1000 460 950 950 460 500 0 760 950 0 0 0 400 700 950 300 950 950>;
		fast_charging_current = <1000 0 0 1200 460 1000 1000 460 500 0 900 1000 0 0 0 400 700 1000 300 1000 1000>;
		full_check_current_1st = <250 0 0 250 250 250 250 250 250 0 250 250 0 0 0 250 250 250 250 250 250>;
		full_check_current_2nd = <2400 0 0 2400 2400 2400 2400 2400 2400 0 2400 2400 0 0 0 2400 2400 2400 2400 2400 2400>;

		adc_check_count = <5>;

		cable_check_type = <5>; /* SEC_BATTERY_CABLE_CHECK_PSY | NOUSB*/
		cable_source_type = <1>; /* SEC_BATTERY_CABLE_SOURCE_EXTERNAL */
		event_waiting_time = <600>;
		polling_type = <1>; /* SEC_BATTERY_MONITOR_ALARM */
		monitor_initial_count = <0>;

		battery_check_type = <4>; /* SEC_BATTERY_CHECK_FUELGAUGE */
		check_count = <0>;
		check_adc_max = <1440>;
		check_adc_min = <0>;

		ovp_uvlo_check_type = <4>; /* SEC_BATTERY_OVP_UVLO_CHGINT */

		thermal_source = <0>; /* SEC_BATTERY_THERMAL_SOURCE_FG */

		temp_check_type = <2>; /* _BATTERY_TEMP_CHECK_TEMP */
		temp_check_count = <1>;
		temp_high_threshold_event = <600>;
		temp_high_recovery_event = <460>;
		temp_low_threshold_event = <(-30)>;
		temp_low_recovery_event = <0>;
		temp_high_threshold_normal = <540>;
		temp_high_recovery_normal = <460>;
		temp_low_threshold_normal = <(-50)>;
		temp_low_recovery_normal = <30>;
		temp_high_threshold_lpm = <540>;
		temp_high_recovery_lpm = <460>;
		temp_low_threshold_lpm = <(-50)>;
		temp_low_recovery_lpm = <30>;
		full_check_type = <7>; /* SEC_BATTERY_FULLCHARGED_CHGPSY */
		full_check_type_2nd = <3>; /* SEC_BATTERY_FULLCHARGED_TIME */
		full_check_count = <1>;
		chg_gpio_full_check = <0>;
		chg_polarity_full_check = <1>;

		/* SEC_BATTERY_FULL_CONDITION_SOC |
		   SEC_BATTERY_FULL_CONDITION_NOTIMEFULL |
		   SEC_BATTERY_FULL_CONDITION_VCELL */
		full_condition_type = <13>;
		full_condition_soc = <100>;
		full_condition_vcell = <4300>;

		recharge_check_count = <2>;
		recharge_condition_type = <4>; /* SEC_BATTERY_RECHARGE_CONDITION_VCELL */
		recharge_condition_soc = <98>;
		recharge_condition_vcell = <4300>;

		charging_total_time = <21600>;
		recharging_total_time = <5400>;
		charging_reset_time = <0>;
	};

	sec-fuelgauge {
		capacity-max = <1000>;
		capacity-max-margin = <30>;
		capacity-min = <0>;
		fg-irq-attr = <IRQ_TYPE_EDGE_FALLING>;
		fuel-alert-soc = <1>;
		temp_adc_channel = <2>; /* PM822_GPADC2 */
	};

	vibrator: vibrator {
	compatible = "marvell,android-vibrator";
	pinctrl-names = "default";
	pinctrl-0 = <&vib_gpio_pmx>;
	android_vibrator,vib_ldo_en = <&gpio 96 GPIO_ACTIVE_HIGH>;
	};

	panel {
		compatible = "marvell,mmp-dsi-panel";
		pinctrl-names = "default", "enable", "disable";
		pinctrl-0 = <&lcd_pmx &lcd_rst_pmx &lcd_esd_pmx>;
		pinctrl-1 = <&lcd_rst_pmx>;
		pinctrl-2 = <&lcd_rst_pmx_sleep>;
		marvell,path-name = "mmp_pnpath";
		marvell,dsi-panel = <&mmp_dsi_panel>;
		interrupt-parent = <&gpio>;
		interrupts = <6 IRQ_TYPE_EDGE_RISING>;
		marvell,panel-esd-en;
		marvell,panel-esd-gpio = <&gpio 19 0>;
		marvell,panel-esd-type = <IRQ_TYPE_EDGE_RISING>;
		marvell,panel-backlight = <&backlight>;
		panel-ext-pin {
			/*
			 * Three properties are required
			 * to control pwr pin
			 * @node : panel-ext-pin node
			 * @on : <0> - off / <1> - on
			 * @usec : delay time of usec
			 */
			panel-ext-pin-on = <
				&panel_pwr_vcc	1 0
				&panel_pwr_vdd	1 0
				&panel_pwr_rst	1 20
				&panel_pwr_rst	0 2000
				&panel_pwr_rst	1 5000
				>;
			panel-ext-pin-off = <
				&panel_pwr_rst	0 10
				&panel_pwr_vcc	0 10
				&panel_pwr_vdd	0 10
				>;
			/*
			 * There are four properties to define pwr pin
			 * <prefix>-name : pin name
			 * <prefix>-type : <0> - GPIO, <1> - PMIC Regulator
			 * <prefix>-gpio : If the type is GPIO, assign a gpio.
			 * <prefix>-supply : If the type is PMIC Regulator, assign a regulator.
			 */

			panel_pwr_rst: panel-pwr-rst {
				panel-ext-pin-name = "rst";
				panel-ext-pin-type = <EXT_PIN_GPIO>;
				panel-ext-pin-gpio = <&gpio 18 0>;
			};
			panel_pwr_vcc: panel-pwr-vcc {
				panel-ext-pin-name = "vcc";
				panel-ext-pin-type = <EXT_PIN_GPIO>;
				panel-ext-pin-gpio = <&gpio 6 0>;
			};
			panel_pwr_vdd: panel-pwr-vdd {
				panel-ext-pin-name = "vdd";
				panel-ext-pin-type = <EXT_PIN_GPIO>;
				panel-ext-pin-gpio = <&gpio 7 0>;
			};
		};
		mmp_dsi_panel: mmp-dsi-panel {};
	};

	panel-modes {
		/*
		 * xres and yres are added for calculating
		 * framebuffer size.
		 * If this node is not added, it will take default
		 * size defined in drivers/video/mmp/setup.c
		 */
		compatible = "mmp-panel-modes";
		xres = <800>;
		yres = <1280>;
	};

	backlight: mmp-panel-backlight {
		compatible = "marvell,mmp-panel-backlight";
		marvell,panel-backlight-name = "panel";
		marvell,panel-backlight-brt-range = <
			0	0	/* OFF */
			10	2	/* DIM */
			10	2	/* MIN */
			143	73	/* DEF */
			255	170	/* MAX */
		>;
	};

	gps: mmp-gps {
		compatible = "marvell,mmp-gps";
		marvell,gps-eclk-ctrl;

		vgps-supply = <&ldo13>;

		pinctrl-names = "default", "idle";
		pinctrl-0 = <&gps_pmx_eclk &gps_pmx_poweronoff &gps_pmx_reset>;
		pinctrl-1 = <&gps_pmx_gpio>;

		on-off-gpio = <&gpio 4 0>;
		reset-n-gpio = <&gpio 5 0>;
	};
	dip {
		compatible = "marvell,simple-dip";
	};
	sec-thermistor {
		compatible = "samsung,sec-thermistor";
		status = "okay";
		adc-channel = <1>;

		adc_array = <69 75 81 87 93 99 106 113 120 127 135 142 149 156 163 170 180 188 196 204 212 220
				 228 236 244 252 261 270 279 288 297 306 315 324 333 342 359 373 387 401 415 429 443
				 457 471 485 505 525 545 565 590 610 635 660 680 703 733 765 825 860 870 890 928 952
				 988 1030 1075 1120 1170 1207 1263 1312 1355 1356 1357 1358 1359 1360 1361 1362 1363
				 1364 1365 1366 1367 1368>;

		temp_array = <750 740 730 720 710 700 690 680 670 660 650 640 630 620 610 600 590 580 570 560
				 550 540 530 520 510 500 490 480 470 460 450 440 430 420 410 400 390 380 370 360 350
				 340 330 320 310 300 290 280 270 260 250 240 230 220 210 200 190 180 170 160 150 140
				 130 120 110 100 90 80 70 60 50 40 30 20 10 0 (-10) (-20) (-30) (-40) (-50) (-60) (-70)
				 (-80) (-90) (-100)>;
	};
};
/include/ "88pm8xx.dtsi"
&pmic {
	regulators {
		BUCK4 {
			regulator-compatible = "88PM800-BUCK4";
			regulator-min-microvolt = <600000>;
			regulator-max-microvolt = <3300000>;
			regulator-boot-on;
			regulator-always-on;
		};
		LDO6 {
			regulator-compatible = "88PM800-LDO6";
			regulator-min-microvolt = <1200000>;
			regulator-max-microvolt = <3300000>;
		};
		LDO7 {
			regulator-compatible = "88PM800-LDO7";
			regulator-min-microvolt = <1200000>;
			regulator-max-microvolt = <3300000>;
			regulator-boot-on;
			regulator-always-on;
		};
	};
	headset {
		compatible = "marvell,88pm80x-headset";
		marvell,switch-name = "h2w";
		marvell,headset-flag = <0>;
		/* Should be checked value adc '4pole Min' between 'Button max' */
		marvell,press-release-th = <950>;
		marvell,micbias-supply = <&ldo14>;

		marvell,hook-press-th = <70>;
		marvell,vol-up-press-th = <300>;
		marvell,vol-down-press-th = <800>;
		marvell,mic-det-th = <600>;

		pinctrl-names = "default";
		pinctrl-0 = <&gdet_gpio>;

		headset-gdet-gpio = <&gpio 97 0>;

		/* Samsung Headset Driver data (KSND) */
		/* adc == 0, default to 3pole if it stays
		 * in this range for 40ms (20ms delays, 2 samples)
		 */
		sec0,adc_high = <0>;
		sec0,delay_ms = <20>;
		sec0,check_count = <2>;
		sec0,jack_type = <2>;  /* SEC_HEADSET_3POLE */

		/* 0 < adc <= 980, unstable zone, default to 3pole if it stays
		 * in this range for a 100ms (20ms delays, 5 samples)
		 */
		sec1,adc_high = <1001>;
		sec1,delay_ms = <20>;
		sec1,check_count = <5>;
		sec1,jack_type = <2>; /* SEC_HEADSET_3POLE */

		/* 980 < adc <= 1000, unstable zone, default to 4pole if it
		 * stays in this range for 200ms (20ms delays, 10 samples)
		 */
		sec2,adc_high = <1002>;
		sec2,delay_ms = <20>;
		sec2,check_count = <10>;
		sec2,jack_type = <1>; /* SEC_HEADSET_4POLE */

		/* 1000 < adc <= 1399, default to 4 pole if it stays */
		/* in this range for 40ms (20ms delays, 2 samples)
		 */
		sec3,adc_high = <1700>;
		sec3,delay_ms = <20>;
		sec3,check_count = <2>;
		sec3,jack_type = <1>; /* SEC_HEADSET_4POLE */

		/* adc > 1400, unstable zone, default to 3pole if it stays
		 * in this range for a second (10ms delays, 100 samples)
		 */
		sec4,adc_high = <0x7fffffff>;
		sec4,delay_ms = <10>;
		sec4,check_count = <1000>;
		sec4,jack_type = <2>; /* SEC_HEADSET_3POLE */

		/* to support 3-buttons earjack */
		/* 0 <= adc <=160, stable zone */
		sec_sendend0,code = <0x4000>; /* SND_JACK_BTN_0 */
		sec_sendend0,adc_low =<0>;
		sec_sendend0,adc_high =<170>;

		/* 161 <= adc <= 300, stable zone */
		sec_sendend1,code = <0x2000>; /* SND_JACK_BTN_1 */
		sec_sendend1,adc_low =<171>;
		sec_sendend1,adc_high =<344>;

		/* 321 <= adc <= 700, stable zone */
		sec_sendend2,code = <0x1000>; /* SND_JACK_BTN_2 */
		sec_sendend2,adc_low =<345>;
		sec_sendend2,adc_high =<900>;
	};
};

/include/ "mmp-dsi-panel-s6d7aa0x-boe-wxga-video.dtsi"
/include/ "mmp-dsi-panel-s6d7aa0x-sdc-wxga-video.dtsi"
